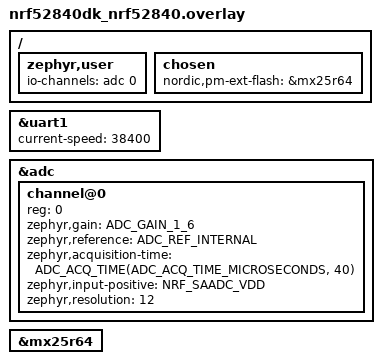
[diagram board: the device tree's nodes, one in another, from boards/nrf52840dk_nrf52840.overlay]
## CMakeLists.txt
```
# SPDX-License-Identifier: Apache-2.0

cmake_minimum_required(VERSION 3.20.0)
find_package(Zephyr REQUIRED HINTS $ENV{ZEPHYR_BASE})
project(sensor_adv_adv)


target_sources(app PRIVATE src/main.c)

#Módulo Local
add_subdirectory(src/modules/parser_gnss)

#Módulo Comum Obrigatório
add_subdirectory(../common/src/sensor_common ${CMAKE_CURRENT_BINARY_DIR}/sensor_common)
add_subdirectory(../common/src/sensor_ble ${CMAKE_CURRENT_BINARY_DIR}/sensor_ble)

#Módulo Comum Opcional
add_subdirectory_ifdef(CONFIG_BATTERY_LEVEL ../common/src/battery_level ${CMAKE_CURRENT_BINARY_DIR}/battery_level)
add_subdirectory_ifdef(CONFIG_SENSOR_BLE_SERVICE ../common/src/sensor_ble_service ${CMAKE_CURRENT_BINARY_DIR}/sensor_ble_service)
```

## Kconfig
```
#
# Copyright (c) 2024 Nordic Semiconductor ASA
#
# SPDX-License-Identifier: LicenseRef-Nordic-5-Clause
#

menu "Sensor GNSS ADV"



rsource "src/modules/parser_gnss/Kconfig.parser_gnss"
rsource "../common/src/sensor_common/Kconfig.sensor_common"
rsource "../common/src/sensor_ble/Kconfig.sensor_ble"
rsource "../common/src/sensor_ble_service/Kconfig.sensor_ble_service"
rsource "../common/src/battery_level/Kconfig.battery_level"



endmenu

menu "Zephyr Kernel"
source "Kconfig.zephyr"
endmenu
```

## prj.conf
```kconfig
#Common to all sensors
CONFIG_CBPRINTF_FP_SUPPORT=y
CONFIG_LOG=y

#UART GNSS
CONFIG_SERIAL=y
CONFIG_UART_INTERRUPT_DRIVEN=y

CONFIG_PM_DEVICE=y

#Bluetooth
CONFIG_BT=y
CONFIG_BT_DEVICE_NAME="Sensor GNSS Adv"

#Peripheral
CONFIG_BT_PERIPHERAL=y
CONFIG_SENSOR_BLE_SERVICE=y

#DFU
CONFIG_NCS_SAMPLE_MCUMGR_BT_OTA_DFU=y 

#GATT
CONFIG_BT_GATT_CLIENT=y

#Adjust MTU size for GATT
CONFIG_BT_USER_DATA_LEN_UPDATE=y
CONFIG_BT_CTLR_DATA_LENGTH_MAX=251
CONFIG_BT_BUF_ACL_RX_SIZE=251
CONFIG_BT_BUF_ACL_TX_SIZE=251
CONFIG_BT_L2CAP_TX_MTU=247

#Security 
#CONFIG_BT_SMP=y
#CONFIG_BT_FIXED_PASSKEY=y

#Save BLE Info to Flash
# CONFIG_SETTINGS=y
# CONFIG_BT_SETTINGS=y
# CONFIG_FLASH=y
# CONFIG_FLASH_PAGE_LAYOUT=y
# CONFIG_FLASH_MAP=y
# CONFIG_NVS=y
```

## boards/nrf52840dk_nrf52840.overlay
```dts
// To get started, press Ctrl+Space to bring up the completion menu and view the available nodes.

// You can also use the buttons in the sidebar to perform actions on nodes.
// Actions currently available include:

// * Enabling / disabling the node
// * Adding the bus to a bus
// * Removing the node
// * Connecting ADC channels

// For more help, browse the DeviceTree documentation at https://docs.zephyrproject.org/latest/guides/dts/index.html
// You can also visit the nRF DeviceTree extension documentation at https://docs.nordicsemi.com/bundle/nrf-connect-vscode/page/guides/ncs_configure_app.html#devicetree-support-in-the-extension

/ {
	zephyr,user {
		io-channels = <&adc 0>;
	};
	chosen {
		nordic,pm-ext-flash = &mx25r64;
	};
};
&uart1 {
    status = "okay";
    current-speed = <38400>;

};

&adc {
	#address-cells = <1>;
	#size-cells = <0>;
	status = "okay";
	
	channel@0 {
		reg = <0>;
		zephyr,gain = "ADC_GAIN_1_6";
		zephyr,reference = "ADC_REF_INTERNAL";
		zephyr,acquisition-time = <ADC_ACQ_TIME(ADC_ACQ_TIME_MICROSECONDS, 40)>;
		zephyr,input-positive = <NRF_SAADC_VDD>;
		zephyr,resolution = <12>;
	};
};

&mx25r64 {
	status = "okay";
	};
	
```

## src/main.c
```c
#include <zephyr/kernel.h>
#include <zephyr/logging/log.h>
#include <zephyr/settings/settings.h>
#include "parser_gnss.h"
#include "sensor_common.h"
#include "sensor_ble.h"

#ifdef CONFIG_SENSOR_BLE_SERVICE
#include "sensor_ble_service.h"
#endif // CONFIG_SENSOR_BLE_SERVICE

#define SENSOR_READ_INTERVAL K_SECONDS(10)

LOG_MODULE_REGISTER(sensor_gnss_adv, LOG_LEVEL_INF);

int main(void) {
    sensor_data_t data;

    LOG_INF("Sensor GNSS BLE Initialized.");


    int err = init_ble();
    if (err) {
		LOG_ERR("Failed to Init BLE");
		return -1;
	}

#ifdef CONFIG_BT_SMP
    settings_load();
    bt_ready(err);
#endif // CONFIG_BT_SMP
	
    if (parser_gnss_init() != 0) {
        LOG_ERR("GNSS Initialization Failed!");
        return -1;
    }

    while (1) {
        if (acquire_gnss_fix(&data) == 0) {
            sensor_data_print(&data);
            sensor_data_adv_update(&data);
#ifdef CONFIG_SENSOR_BLE_SERVICE
            send_sensor_data_notification(data);
#endif // CONFIG_SENSOR_BLE_SERVICE

		} else {
		  LOG_ERR("Failed to read sensor data");
		}
#ifdef CONFIG_SENSOR_BLE_SERVICE
        k_sleep(K_SECONDS(sensor_interval_var)); 
#else
        k_sleep(SENSOR_READ_INTERVAL);
#endif // CONFIG_SENSOR_BLE_SERVICE

    }
    return 0;
}
```
